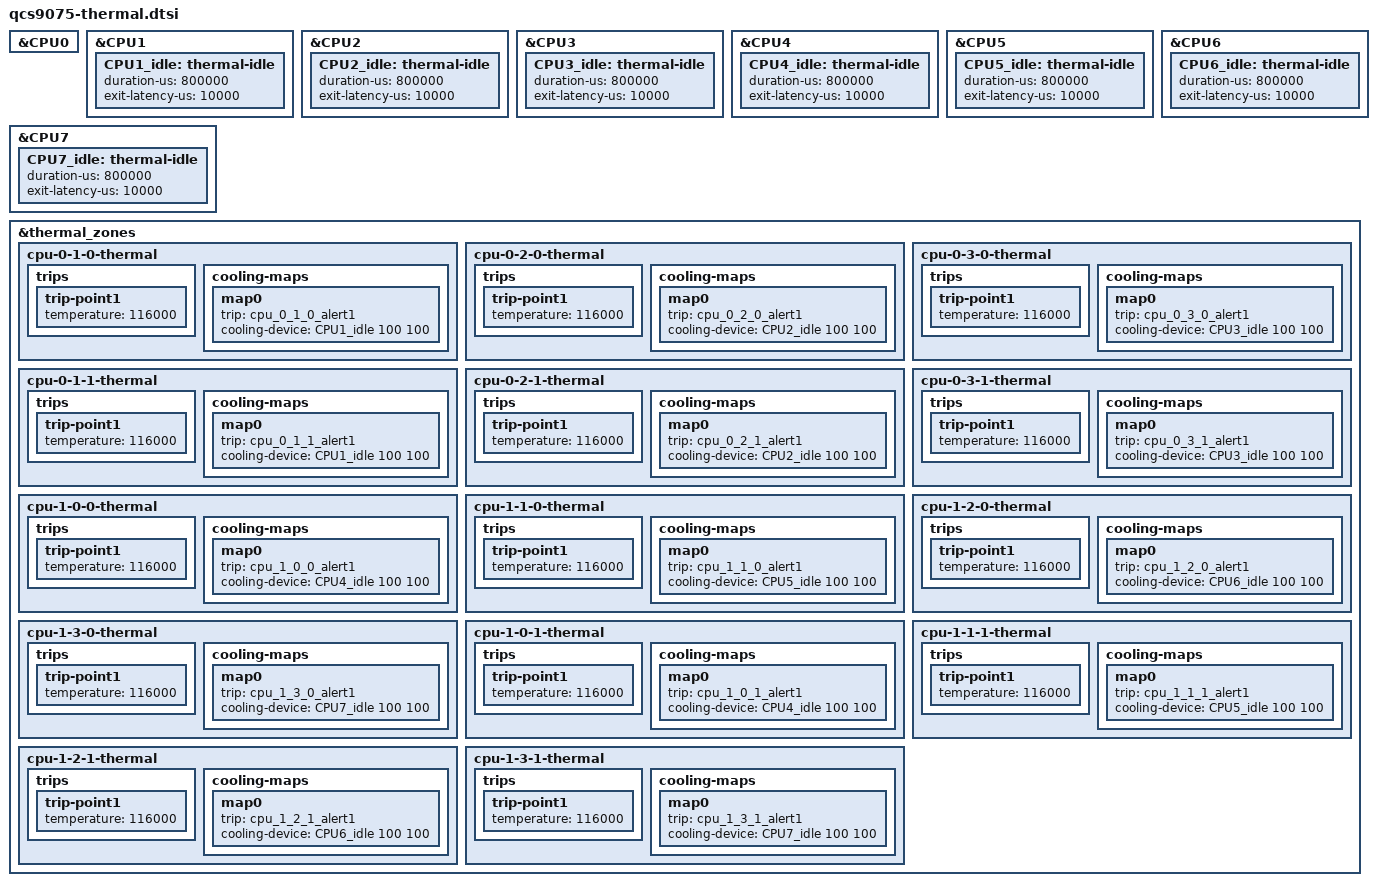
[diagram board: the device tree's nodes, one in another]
// SPDX-License-Identifier: BSD-3-Clause
/*
 * Copyright (c) 2024 Qualcomm Innovation Center, Inc. All rights reserved.
 */

&CPU0 {
	#cooling-cells = <2>;
};

&CPU1 {
	#cooling-cells = <2>;
	CPU1_idle: thermal-idle {
		#cooling-cells = <2>;
		duration-us = <800000>;
		exit-latency-us = <10000>;
	};
};

&CPU2 {
	#cooling-cells = <2>;
	CPU2_idle: thermal-idle {
		#cooling-cells = <2>;
		duration-us = <800000>;
		exit-latency-us = <10000>;
	};
};

&CPU3 {
	#cooling-cells = <2>;
	CPU3_idle: thermal-idle {
		#cooling-cells = <2>;
		duration-us = <800000>;
		exit-latency-us = <10000>;
	};
};

&CPU4 {
	#cooling-cells = <2>;
	CPU4_idle: thermal-idle {
		#cooling-cells = <2>;
		duration-us = <800000>;
		exit-latency-us = <10000>;
	};
};

&CPU5 {
	#cooling-cells = <2>;
	CPU5_idle: thermal-idle {
		#cooling-cells = <2>;
		duration-us = <800000>;
		exit-latency-us = <10000>;
	};
};

&CPU6 {
	#cooling-cells = <2>;
	CPU6_idle: thermal-idle {
		#cooling-cells = <2>;
		duration-us = <800000>;
		exit-latency-us = <10000>;
	};
};

&CPU7 {
	#cooling-cells = <2>;
	CPU7_idle: thermal-idle {
		#cooling-cells = <2>;
		duration-us = <800000>;
		exit-latency-us = <10000>;
	};
};

&thermal_zones {
	cpu-0-1-0-thermal {
		trips {
			trip-point1 {
				temperature = <116000>;
			};
		};

		cooling-maps {
			map0 {
				trip = <&cpu_0_1_0_alert1>;
				cooling-device = <&CPU1_idle 100 100>;
			};
		};
	};

	cpu-0-2-0-thermal {
		trips {
			trip-point1 {
				temperature = <116000>;
			};
		};

		cooling-maps {
			map0 {
				trip = <&cpu_0_2_0_alert1>;
				cooling-device = <&CPU2_idle 100 100>;
			};
		};
	};

	cpu-0-3-0-thermal {
		trips {
			trip-point1 {
				temperature = <116000>;
			};
		};

		cooling-maps {
			map0 {
				trip = <&cpu_0_3_0_alert1>;
				cooling-device = <&CPU3_idle 100 100>;
			};
		};
	};

	cpu-0-1-1-thermal {
		trips {
			trip-point1 {
				temperature = <116000>;
			};
		};

		cooling-maps {
			map0 {
				trip = <&cpu_0_1_1_alert1>;
				cooling-device = <&CPU1_idle 100 100>;
			};
		};
	};

	cpu-0-2-1-thermal {
		trips {
			trip-point1 {
				temperature = <116000>;
			};
		};

		cooling-maps {
			map0 {
				trip = <&cpu_0_2_1_alert1>;
				cooling-device = <&CPU2_idle 100 100>;
			};
		};
	};

	cpu-0-3-1-thermal {
		trips {
			trip-point1 {
				temperature = <116000>;
			};
		};

		cooling-maps {
			map0 {
				trip = <&cpu_0_3_1_alert1>;
				cooling-device = <&CPU3_idle 100 100>;
			};
		};
	};

	cpu-1-0-0-thermal {
		trips {
			trip-point1 {
				temperature = <116000>;
			};
		};

		cooling-maps {
			map0 {
				trip = <&cpu_1_0_0_alert1>;
				cooling-device = <&CPU4_idle 100 100>;
			};
		};
	};

	cpu-1-1-0-thermal {
		trips {
			trip-point1 {
				temperature = <116000>;
			};
		};

		cooling-maps {
			map0 {
				trip = <&cpu_1_1_0_alert1>;
				cooling-device = <&CPU5_idle 100 100>;
			};
		};
	};

	cpu-1-2-0-thermal {
		trips {
			trip-point1 {
				temperature = <116000>;
			};
		};

		cooling-maps {
			map0 {
				trip = <&cpu_1_2_0_alert1>;
				cooling-device = <&CPU6_idle 100 100>;
			};
		};
	};

	cpu-1-3-0-thermal {
		trips {
			trip-point1 {
				temperature = <116000>;
			};
		};

		cooling-maps {
			map0 {
				trip = <&cpu_1_3_0_alert1>;
				cooling-device = <&CPU7_idle 100 100>;
			};
		};
	};

	cpu-1-0-1-thermal {
		trips {
			trip-point1 {
				temperature = <116000>;
			};
		};

		cooling-maps {
			map0 {
				trip = <&cpu_1_0_1_alert1>;
				cooling-device = <&CPU4_idle 100 100>;
			};
		};
	};

	cpu-1-1-1-thermal {
		trips {
			trip-point1 {
				temperature = <116000>;
			};
		};

		cooling-maps {
			map0 {
				trip = <&cpu_1_1_1_alert1>;
				cooling-device = <&CPU5_idle 100 100>;
			};
		};
	};

	cpu-1-2-1-thermal {
		trips {
			trip-point1 {
				temperature = <116000>;
			};
		};

		cooling-maps {
			map0 {
				trip = <&cpu_1_2_1_alert1>;
				cooling-device = <&CPU6_idle 100 100>;
			};
		};
	};

	cpu-1-3-1-thermal {
		trips {
			trip-point1 {
				temperature = <116000>;
			};
		};

		cooling-maps {
			map0 {
				trip = <&cpu_1_3_1_alert1>;
				cooling-device = <&CPU7_idle 100 100>;
			};
		};
	};
};
